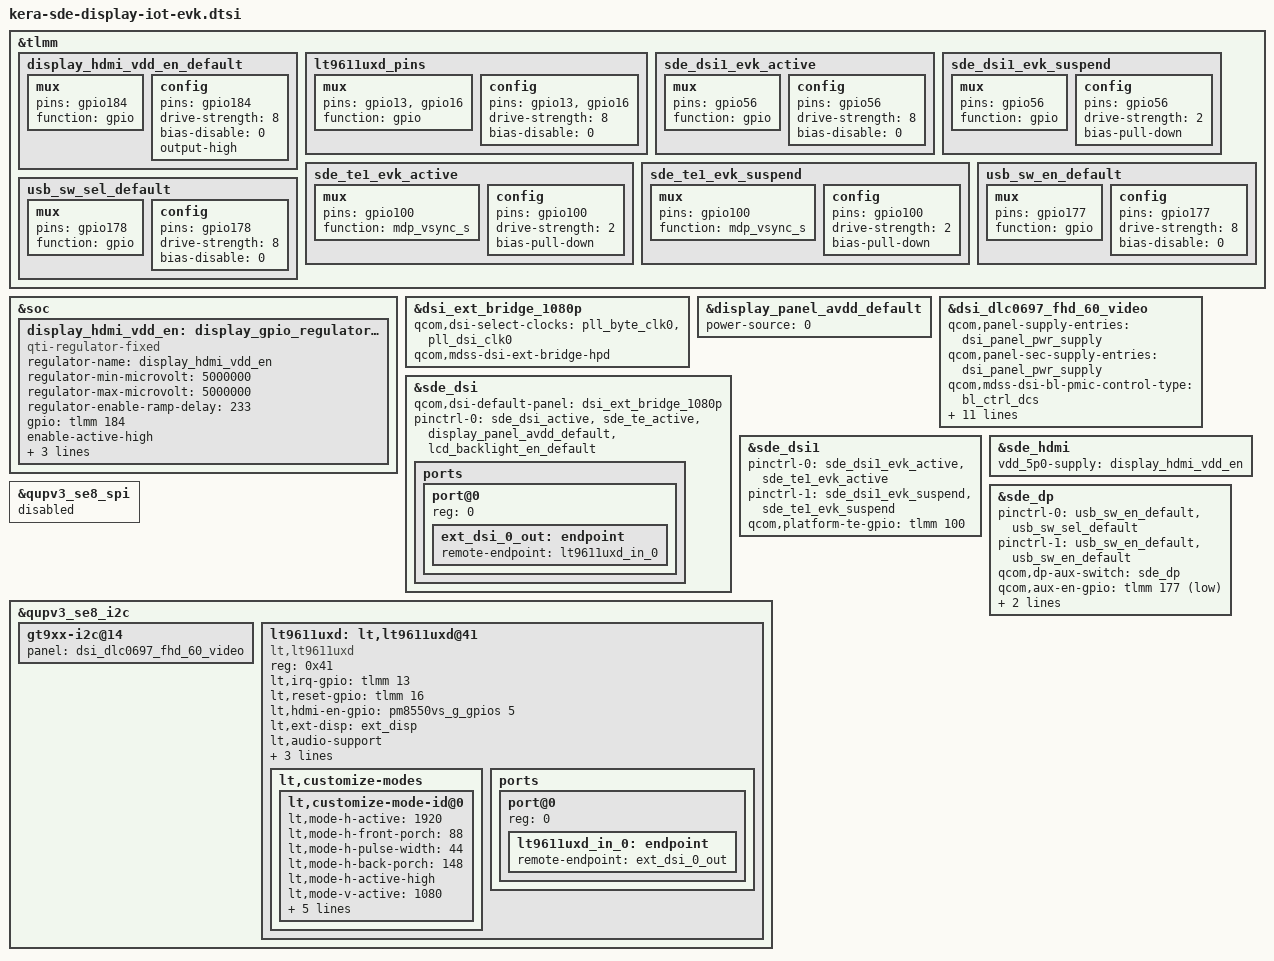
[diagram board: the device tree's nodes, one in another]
// SPDX-License-Identifier: BSD-3-Clause
/*
 * Copyright (c) Qualcomm Technologies, Inc. and/or its subsidiaries.
 */

#include "kera-sde-display-iot-cdp.dtsi"


&tlmm {
	display_hdmi_vdd_en_default: display_hdmi_vdd_en_default {
		mux {
			pins = "gpio184";
			function = "gpio";
		};

		config {
			pins = "gpio184";
			drive-strength = <8>;
			bias-disable = <0>;
			output-high;
		};
	};

	lt9611uxd_pins: lt9611uxd_pins {
		mux {
			pins = "gpio13", "gpio16";
			function = "gpio";
		};

		config {
			pins = "gpio13", "gpio16";
			drive-strength = <8>;
			bias-disable = <0>;
		};
	};

	sde_dsi1_evk_active: sde_dsi1_evk_active {
		mux {
			pins = "gpio56";
			function = "gpio";
		};

		config {
			pins = "gpio56";
			drive-strength = <8>;   /* 8 mA */
			bias-disable = <0>;   /* no pull */
		};
	};

	sde_dsi1_evk_suspend: sde_dsi1_evk_suspend {
		mux {
			pins = "gpio56";
			function = "gpio";
		};

		config {
			pins = "gpio56";
			drive-strength = <2>;   /* 2 mA */
			bias-pull-down;         /* PULL DOWN */
		};
	};

	sde_te1_evk_active: sde_te1_evk_active {
		mux {
			pins = "gpio100";
			function = "mdp_vsync_s";
		};

		config {
			pins = "gpio100";
			drive-strength = <2>;   /* 2 mA */
			bias-pull-down;         /* PULL DOWN */
		};
	};

	sde_te1_evk_suspend: sde_te1_evk_suspend {
		mux {
			pins = "gpio100";
			function = "mdp_vsync_s";
		};

		config {
			pins = "gpio100";
			drive-strength = <2>;   /* 2 mA */
			bias-pull-down;         /* PULL DOWN */
		};
	};

	usb_sw_en_default: usb_sw_en_default {
		mux {
			pins = "gpio177";
			function = "gpio";
		};

		config {
			pins = "gpio177";
			drive-strength = <8>;
			bias-disable = <0>;
		};
	};

	usb_sw_sel_default: usb_sw_sel_default {
		mux {
			pins = "gpio178";
			function = "gpio";
		};

		config {
			pins = "gpio178";
			drive-strength = <8>;
			bias-disable = <0>;
		};
	};
};

&soc {
	display_hdmi_vdd_en: display_gpio_regulator@1 {
		compatible = "qti-regulator-fixed";
		regulator-name = "display_hdmi_vdd_en";
		regulator-min-microvolt = <5000000>;
		regulator-max-microvolt = <5000000>;
		regulator-enable-ramp-delay = <233>;
		gpio = <&tlmm 184 0>;
		enable-active-high;
		proxy-supply = <&display_hdmi_vdd_en>;
		qcom,proxy-consumer-enable;
		pinctrl-names = "default";
		pinctrl-0 = <&display_hdmi_vdd_en_default>;
	};
};

&dsi_ext_bridge_1080p {
	qcom,dsi-select-clocks = "pll_byte_clk0", "pll_dsi_clk0";
	qcom,mdss-dsi-ext-bridge-hpd;
};

&display_panel_avdd_default {
	power-source = <0>;  /* 1.8V */
};

&dsi_dlc0697_fhd_60_video {
	qcom,panel-supply-entries = <&dsi_panel_pwr_supply>;
	qcom,panel-sec-supply-entries = <&dsi_panel_pwr_supply>;
	qcom,mdss-dsi-bl-pmic-control-type = "bl_ctrl_dcs";
	qcom,mdss-dsi-sec-bl-pmic-control-type = "bl_ctrl_dcs";
	qcom,mdss-dsi-bl-min-level = <20>;
	qcom,mdss-dsi-bl-max-level = <4095>;
	qcom,mdss-brightness-max-level = <8191>;
	qcom,mdss-dsi-bl-inverted-dbv;
	qcom,platform-reset-gpio = <&tlmm 12 0>;
	qcom,platform-sec-reset-gpio = <&tlmm 56 0>;
	qcom,platform-bklight-en-gpio = <&pmxr2230_gpios 2 0>;
	qcom,platform-en-gpio = <&pm8550vs_g_gpios 5 0>;
};

&sde_dsi {
	qcom,dsi-default-panel = <&dsi_ext_bridge_1080p>;
	pinctrl-0 = <&sde_dsi_active &sde_te_active
		&display_panel_avdd_default
		&lcd_backlight_en_default>;

	ports {
		#address-cells = <1>;
		#size-cells = <0>;

		port@0 {
			reg = <0>;
			ext_dsi_0_out: endpoint {
				remote-endpoint = <&lt9611uxd_in_0>;
			};
		};
	};
};

&sde_dsi1 {
	pinctrl-0 = <&sde_dsi1_evk_active &sde_te1_evk_active>;
	pinctrl-1 = <&sde_dsi1_evk_suspend &sde_te1_evk_suspend>;
	qcom,platform-te-gpio = <&tlmm 100 0>;
};

&sde_hdmi {
	vdd_5p0-supply = <&display_hdmi_vdd_en>;
};

&qupv3_se8_spi {
	status = "disabled";
};

&qupv3_se8_i2c {
	status = "okay";

	gt9xx-i2c@14 {
		panel = <&dsi_dlc0697_fhd_60_video>;
	};

	lt9611uxd: lt,lt9611uxd@41 {
		compatible = "lt,lt9611uxd";
		reg = <0x41>;
		lt,irq-gpio = <&tlmm 13 0x0>;
		lt,reset-gpio = <&tlmm 16 0x0>;
		lt,hdmi-en-gpio = <&pm8550vs_g_gpios 5 0>;
		lt,ext-disp = <&ext_disp>;
		lt,audio-support;
		lt,cec-support;

		pinctrl-names = "default";
		pinctrl-0 = <&lt9611uxd_pins>;

		lt,preferred-mode = "1920x1080";

		lt,customize-modes {
			lt,customize-mode-id@0 {
				lt,mode-h-active = <1920>;
				lt,mode-h-front-porch = <88>;
				lt,mode-h-pulse-width = <44>;
				lt,mode-h-back-porch = <148>;
				lt,mode-h-active-high;
				lt,mode-v-active = <1080>;
				lt,mode-v-front-porch = <4>;
				lt,mode-v-pulse-width = <5>;
				lt,mode-v-back-porch = <36>;
				lt,mode-v-active-high;
				lt,mode-clock-in-khz = <148500>;
			};
		};

		ports {
			#address-cells = <1>;
			#size-cells = <0>;

			port@0 {
				reg = <0>;
				lt9611uxd_in_0: endpoint {
					remote-endpoint = <&ext_dsi_0_out>;
				};
			};
		};
	};
};

&sde_dp {
	pinctrl-names = "mdss_dp_active", "mdss_dp_sleep";
	pinctrl-0 = <&usb_sw_en_default &usb_sw_sel_default>;
	pinctrl-1 = <&usb_sw_en_default &usb_sw_en_default>;
	qcom,dp-aux-switch = <&sde_dp>;
	qcom,aux-en-gpio = <&tlmm 177 1>;
	qcom,aux-sel-gpio = <&tlmm 178 0>;
	qcom,dp-gpio-aux-switch;
};
